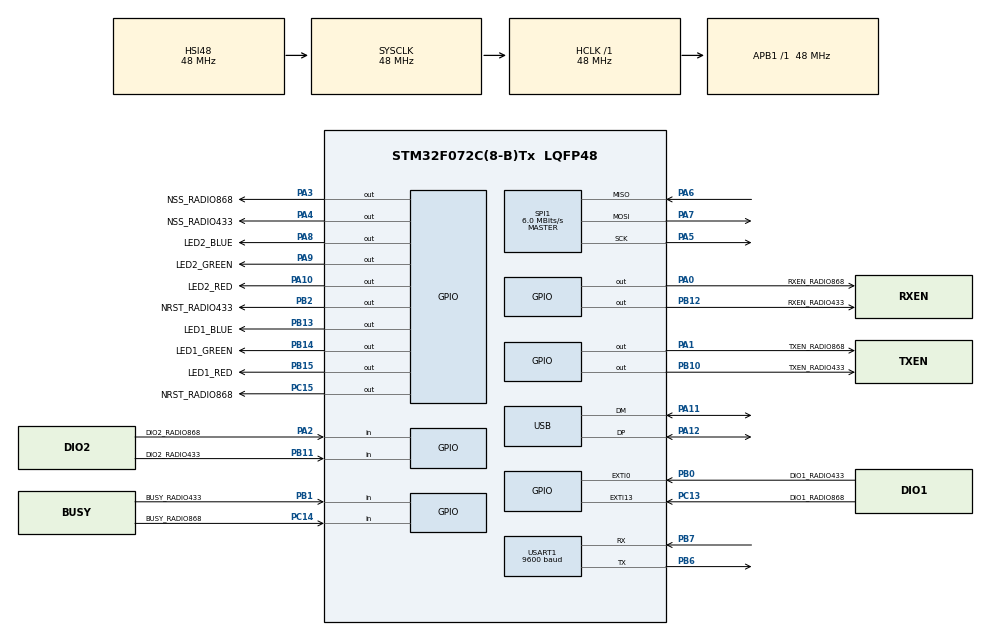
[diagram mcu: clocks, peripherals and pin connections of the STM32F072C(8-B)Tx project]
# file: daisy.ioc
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Mcu.Family=STM32F0
Mcu.Name=STM32F072C(8-B)Tx
Mcu.Package=LQFP48
NVIC.EXTI0_1_IRQn=true\:0\:0\:false\:false\:true\:true\:true
NVIC.EXTI4_15_IRQn=true\:0\:0\:false\:false\:true\:true\:true
NVIC.USART1_IRQn=true\:0\:0\:false\:false\:true\:true\:true
NVIC.USB_IRQn=true\:0\:0\:false\:false\:true\:false\:true
PA0.GPIO_Label=RXEN_RADIO868
PA0.Signal=GPIO_Output
PA1.GPIO_Label=TXEN_RADIO868
PA1.Signal=GPIO_Output
PA10.GPIO_Label=LED2_RED
PA10.Signal=GPIO_Output
PA11.Mode=Device
PA11.Signal=USB_DM
PA12.Mode=Device
PA12.Signal=USB_DP
PA13.Mode=Serial_Wire
PA13.Signal=SYS_SWDIO
PA14.Mode=Serial_Wire
PA14.Signal=SYS_SWCLK
PA2.GPIO_Label=DIO2_RADIO868
PA2.GPIO_PuPd=GPIO_PULLUP
PA2.Signal=GPIO_Input
PA3.GPIO_Label=NSS_RADIO868
PA3.PinState=GPIO_PIN_SET
PA3.Signal=GPIO_Output
PA4.GPIO_Label=NSS_RADIO433
PA4.PinState=GPIO_PIN_SET
PA4.Signal=GPIO_Output
PA5.Mode=Full_Duplex_Master
PA5.Signal=SPI1_SCK
PA6.GPIO_PuPd=GPIO_PULLUP
PA6.Mode=Full_Duplex_Master
PA6.Signal=SPI1_MISO
PA7.Mode=Full_Duplex_Master
PA7.Signal=SPI1_MOSI
PA8.GPIO_Label=LED2_BLUE
PA8.Signal=GPIO_Output
PA9.GPIO_Label=LED2_GREEN
PA9.Signal=GPIO_Output
PB0.GPIO_Label=DIO1_RADIO433
PB0.GPIO_ModeDefaultEXTI=GPIO_MODE_IT_RISING
PB0.GPIO_PuPd=GPIO_PULLDOWN
PB0.Signal=GPXTI0
PB1.GPIO_Label=BUSY_RADIO433
PB1.Signal=GPIO_Input
PB10.GPIO_Label=TXEN_RADIO433
PB10.Signal=GPIO_Output
PB11.GPIO_Label=DIO2_RADIO433
PB11.GPIO_PuPd=GPIO_PULLUP
PB11.Signal=GPIO_Input
PB12.GPIO_Label=RXEN_RADIO433
PB12.Signal=GPIO_Output
PB13.GPIO_Label=LED1_BLUE
PB13.Signal=GPIO_Output
PB14.GPIO_Label=LED1_GREEN
PB14.Signal=GPIO_Output
PB15.GPIO_Label=LED1_RED
PB15.Signal=GPIO_Output
PB2.GPIO_Label=NRST_RADIO433
PB2.Signal=GPIO_Output
PB6.Mode=Asynchronous
PB6.Signal=USART1_TX
PB7.GPIO_PuPd=GPIO_PULLUP
PB7.Mode=Asynchronous
PB7.Signal=USART1_RX
PC13.GPIO_Label=DIO1_RADIO868
PC13.GPIO_ModeDefaultEXTI=GPIO_MODE_IT_RISING
PC13.GPIO_PuPd=GPIO_PULLDOWN
PC13.Signal=GPXTI13
PC14-OSC32_IN.GPIO_Label=BUSY_RADIO868
PC14-OSC32_IN.Signal=GPIO_Input
PC15-OSC32_OUT.GPIO_Label=NRST_RADIO868
PC15-OSC32_OUT.Signal=GPIO_Output
ProjectManager.HeapSize=0x200
ProjectManager.StackSize=0x400
ProjectManager.TargetToolchain=STM32CubeIDE
RCC.AHBFreq_Value=48000000
RCC.APB1Freq_Value=48000000
RCC.APB1TimFreq_Value=48000000
RCC.HCLKFreq_Value=48000000
RCC.SYSCLKFreq_VALUE=48000000
RCC.SYSCLKSource=RCC_SYSCLKSOURCE_HSI48
SPI1.BaudRatePrescaler=SPI_BAUDRATEPRESCALER_8
SPI1.CalculateBaudRate=6.0 MBits/s
SPI1.DataSize=SPI_DATASIZE_8BIT
SPI1.Direction=SPI_DIRECTION_2LINES
SPI1.Mode=SPI_MODE_MASTER
SPI1.VirtualType=VM_MASTER
USART1.BaudRate=9600
USART1.OverrunDisableParam=ADVFEATURE_OVERRUN_DISABLE
USART1.VirtualMode-Asynchronous=VM_ASYNC
USB_DEVICE.CLASS_NAME_FS=CDC
USB_DEVICE.VirtualMode=Cdc
USB_DEVICE.VirtualModeFS=Cdc_FS
VP_RCC_USB.Mode=CRS SYNC Source USB
VP_USB_DEVICE_VS_USB_DEVICE_CDC_FS.Mode=CDC_FS
board=custom

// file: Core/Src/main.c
/* USER CODE BEGIN Header */
/**
  ******************************************************************************
  * @file           : main.c
  * @brief          : Main program body
  ******************************************************************************
  * @attention
  *
  * <h2><center>&copy; Copyright (c) 2020 STMicroelectronics.
  * All rights reserved.</center></h2>
  *
  * This software component is licensed by ST under Ultimate Liberty license
  * SLA0044, the "License"; You may not use this file except in compliance with
  * the License. You may obtain a copy of the License at:
  *                             www.st.com/SLA0044
  *
  ******************************************************************************
  */
/* USER CODE END Header */
#include "main.h"
#include "usb_device.h"

SPI_HandleTypeDef hspi1;

UART_HandleTypeDef huart1;

void SystemClock_Config(void);
static void MX_GPIO_Init(void);
static void MX_SPI1_Init(void);
static void MX_USART1_UART_Init(void);

int main(void)
{

  /* MCU Configuration--------------------------------------------------------*/

  /* Reset of all peripherals, Initializes the Flash interface and the Systick. */
  HAL_Init();

  /* Configure the system clock */
  SystemClock_Config();

  /* Initialize all configured peripherals */
  MX_GPIO_Init();
  MX_SPI1_Init();
  MX_USB_DEVICE_Init();
  MX_USART1_UART_Init();
  /* USER CODE BEGIN 2 */
  extern void SetupDaisy(void);
  SetupDaisy();

  /* USER CODE END 2 */

  /* Infinite loop */
  while (1)
  {

    /* USER CODE BEGIN 3 */
    extern void LoopDaisy(void);
    LoopDaisy();
  }
  /* USER CODE END 3 */
}

void SystemClock_Config(void)
{
  RCC_OscInitTypeDef RCC_OscInitStruct = {0};
  RCC_ClkInitTypeDef RCC_ClkInitStruct = {0};
  RCC_PeriphCLKInitTypeDef PeriphClkInit = {0};
  RCC_CRSInitTypeDef RCC_CRSInitStruct = {0};

  /** Initializes the RCC Oscillators according to the specified parameters
  * in the RCC_OscInitTypeDef structure.
  */
  RCC_OscInitStruct.OscillatorType = RCC_OSCILLATORTYPE_HSI48;
  RCC_OscInitStruct.HSI48State = RCC_HSI48_ON;
  RCC_OscInitStruct.PLL.PLLState = RCC_PLL_NONE;
  if (HAL_RCC_OscConfig(&RCC_OscInitStruct) != HAL_OK)
  {
    Error_Handler();
  }
  /** Initializes the CPU, AHB and APB buses clocks
  */
  RCC_ClkInitStruct.ClockType = RCC_CLOCKTYPE_HCLK|RCC_CLOCKTYPE_SYSCLK
                              |RCC_CLOCKTYPE_PCLK1;
  RCC_ClkInitStruct.SYSCLKSource = RCC_SYSCLKSOURCE_HSI48;
  RCC_ClkInitStruct.AHBCLKDivider = RCC_SYSCLK_DIV1;
  RCC_ClkInitStruct.APB1CLKDivider = RCC_HCLK_DIV1;

  if (HAL_RCC_ClockConfig(&RCC_ClkInitStruct, FLASH_LATENCY_1) != HAL_OK)
  {
    Error_Handler();
  }
  PeriphClkInit.PeriphClockSelection = RCC_PERIPHCLK_USB|RCC_PERIPHCLK_USART1;
  PeriphClkInit.Usart1ClockSelection = RCC_USART1CLKSOURCE_PCLK1;
  PeriphClkInit.UsbClockSelection = RCC_USBCLKSOURCE_HSI48;

  if (HAL_RCCEx_PeriphCLKConfig(&PeriphClkInit) != HAL_OK)
  {
    Error_Handler();
  }
  /** Enable the SYSCFG APB clock
  */
  __HAL_RCC_CRS_CLK_ENABLE();
  /** Configures CRS
  */
  RCC_CRSInitStruct.Prescaler = RCC_CRS_SYNC_DIV1;
  RCC_CRSInitStruct.Source = RCC_CRS_SYNC_SOURCE_USB;
  RCC_CRSInitStruct.Polarity = RCC_CRS_SYNC_POLARITY_RISING;
  RCC_CRSInitStruct.ReloadValue = __HAL_RCC_CRS_RELOADVALUE_CALCULATE(48000000,1000);
  RCC_CRSInitStruct.ErrorLimitValue = 34;
  RCC_CRSInitStruct.HSI48CalibrationValue = 32;

  HAL_RCCEx_CRSConfig(&RCC_CRSInitStruct);
}

static void MX_SPI1_Init(void)
{

  /* SPI1 parameter configuration*/
  hspi1.Instance = SPI1;
  hspi1.Init.Mode = SPI_MODE_MASTER;
  hspi1.Init.Direction = SPI_DIRECTION_2LINES;
  hspi1.Init.DataSize = SPI_DATASIZE_8BIT;
  hspi1.Init.CLKPolarity = SPI_POLARITY_LOW;
  hspi1.Init.CLKPhase = SPI_PHASE_1EDGE;
  hspi1.Init.NSS = SPI_NSS_SOFT;
  hspi1.Init.BaudRatePrescaler = SPI_BAUDRATEPRESCALER_8;
  hspi1.Init.FirstBit = SPI_FIRSTBIT_MSB;
  hspi1.Init.TIMode = SPI_TIMODE_DISABLE;
  hspi1.Init.CRCCalculation = SPI_CRCCALCULATION_DISABLE;
  hspi1.Init.CRCPolynomial = 7;
  hspi1.Init.CRCLength = SPI_CRC_LENGTH_DATASIZE;
  hspi1.Init.NSSPMode = SPI_NSS_PULSE_ENABLE;
  if (HAL_SPI_Init(&hspi1) != HAL_OK)
  {
    Error_Handler();
  }

}

static void MX_USART1_UART_Init(void)
{

  huart1.Instance = USART1;
  huart1.Init.BaudRate = 9600;
  huart1.Init.WordLength = UART_WORDLENGTH_8B;
  huart1.Init.StopBits = UART_STOPBITS_1;
  huart1.Init.Parity = UART_PARITY_NONE;
  huart1.Init.Mode = UART_MODE_TX_RX;
  huart1.Init.HwFlowCtl = UART_HWCONTROL_NONE;
  huart1.Init.OverSampling = UART_OVERSAMPLING_16;
  huart1.Init.OneBitSampling = UART_ONE_BIT_SAMPLE_DISABLE;
  huart1.AdvancedInit.AdvFeatureInit = UART_ADVFEATURE_RXOVERRUNDISABLE_INIT;
  huart1.AdvancedInit.OverrunDisable = UART_ADVFEATURE_OVERRUN_DISABLE;
  if (HAL_UART_Init(&huart1) != HAL_OK)
  {
    Error_Handler();
  }

}

static void MX_GPIO_Init(void)
{
  GPIO_InitTypeDef GPIO_InitStruct = {0};

  /* GPIO Ports Clock Enable */
  __HAL_RCC_GPIOC_CLK_ENABLE();
  __HAL_RCC_GPIOF_CLK_ENABLE();
  __HAL_RCC_GPIOA_CLK_ENABLE();
  __HAL_RCC_GPIOB_CLK_ENABLE();

  /*Configure GPIO pin Output Level */
  HAL_GPIO_WritePin(NRST_RADIO868_GPIO_Port, NRST_RADIO868_Pin, GPIO_PIN_RESET);

  /*Configure GPIO pin Output Level */
  HAL_GPIO_WritePin(GPIOA, RXEN_RADIO868_Pin|TXEN_RADIO868_Pin|LED2_BLUE_Pin|LED2_GREEN_Pin
                          |LED2_RED_Pin, GPIO_PIN_RESET);

  /*Configure GPIO pin Output Level */
  HAL_GPIO_WritePin(GPIOA, NSS_RADIO868_Pin|NSS_RADIO433_Pin, GPIO_PIN_SET);

  /*Configure GPIO pin Output Level */
  HAL_GPIO_WritePin(GPIOB, NRST_RADIO433_Pin|TXEN_RADIO433_Pin|RXEN_RADIO433_Pin|LED1_BLUE_Pin
                          |LED1_GREEN_Pin|LED1_RED_Pin, GPIO_PIN_RESET);

  /*Configure GPIO pin : DIO1_RADIO868_Pin */
  GPIO_InitStruct.Pin = DIO1_RADIO868_Pin;
  GPIO_InitStruct.Mode = GPIO_MODE_IT_RISING;
  GPIO_InitStruct.Pull = GPIO_PULLDOWN;
  HAL_GPIO_Init(DIO1_RADIO868_GPIO_Port, &GPIO_InitStruct);

  /*Configure GPIO pin : BUSY_RADIO868_Pin */
  GPIO_InitStruct.Pin = BUSY_RADIO868_Pin;
  GPIO_InitStruct.Mode = GPIO_MODE_INPUT;
  GPIO_InitStruct.Pull = GPIO_NOPULL;
  HAL_GPIO_Init(BUSY_RADIO868_GPIO_Port, &GPIO_InitStruct);

  /*Configure GPIO pin : NRST_RADIO868_Pin */
  GPIO_InitStruct.Pin = NRST_RADIO868_Pin;
  GPIO_InitStruct.Mode = GPIO_MODE_OUTPUT_PP;
  GPIO_InitStruct.Pull = GPIO_NOPULL;
  GPIO_InitStruct.Speed = GPIO_SPEED_FREQ_LOW;
  HAL_GPIO_Init(NRST_RADIO868_GPIO_Port, &GPIO_InitStruct);

  /*Configure GPIO pins : PF0 PF1 */
  GPIO_InitStruct.Pin = GPIO_PIN_0|GPIO_PIN_1;
  GPIO_InitStruct.Mode = GPIO_MODE_ANALOG;
  GPIO_InitStruct.Pull = GPIO_NOPULL;
  HAL_GPIO_Init(GPIOF, &GPIO_InitStruct);

  /*Configure GPIO pins : RXEN_RADIO868_Pin TXEN_RADIO868_Pin NSS_RADIO868_Pin NSS_RADIO433_Pin
                           LED2_BLUE_Pin LED2_GREEN_Pin LED2_RED_Pin */
  GPIO_InitStruct.Pin = RXEN_RADIO868_Pin|TXEN_RADIO868_Pin|NSS_RADIO868_Pin|NSS_RADIO433_Pin
                          |LED2_BLUE_Pin|LED2_GREEN_Pin|LED2_RED_Pin;
  GPIO_InitStruct.Mode = GPIO_MODE_OUTPUT_PP;
  GPIO_InitStruct.Pull = GPIO_NOPULL;
  GPIO_InitStruct.Speed = GPIO_SPEED_FREQ_LOW;
  HAL_GPIO_Init(GPIOA, &GPIO_InitStruct);

  /*Configure GPIO pin : DIO2_RADIO868_Pin */
  GPIO_InitStruct.Pin = DIO2_RADIO868_Pin;
  GPIO_InitStruct.Mode = GPIO_MODE_INPUT;
  GPIO_InitStruct.Pull = GPIO_PULLUP;
  HAL_GPIO_Init(DIO2_RADIO868_GPIO_Port, &GPIO_InitStruct);

  /*Configure GPIO pin : DIO1_RADIO433_Pin */
  GPIO_InitStruct.Pin = DIO1_RADIO433_Pin;
  GPIO_InitStruct.Mode = GPIO_MODE_IT_RISING;
  GPIO_InitStruct.Pull = GPIO_PULLDOWN;
  HAL_GPIO_Init(DIO1_RADIO433_GPIO_Port, &GPIO_InitStruct);

  /*Configure GPIO pin : BUSY_RADIO433_Pin */
  GPIO_InitStruct.Pin = BUSY_RADIO433_Pin;
  GPIO_InitStruct.Mode = GPIO_MODE_INPUT;
  GPIO_InitStruct.Pull = GPIO_NOPULL;
  HAL_GPIO_Init(BUSY_RADIO433_GPIO_Port, &GPIO_InitStruct);

  /*Configure GPIO pins : NRST_RADIO433_Pin TXEN_RADIO433_Pin RXEN_RADIO433_Pin LED1_BLUE_Pin
                           LED1_GREEN_Pin LED1_RED_Pin */
  GPIO_InitStruct.Pin = NRST_RADIO433_Pin|TXEN_RADIO433_Pin|RXEN_RADIO433_Pin|LED1_BLUE_Pin
                          |LED1_GREEN_Pin|LED1_RED_Pin;
  GPIO_InitStruct.Mode = GPIO_MODE_OUTPUT_PP;
  GPIO_InitStruct.Pull = GPIO_NOPULL;
  GPIO_InitStruct.Speed = GPIO_SPEED_FREQ_LOW;
  HAL_GPIO_Init(GPIOB, &GPIO_InitStruct);

  /*Configure GPIO pin : DIO2_RADIO433_Pin */
  GPIO_InitStruct.Pin = DIO2_RADIO433_Pin;
  GPIO_InitStruct.Mode = GPIO_MODE_INPUT;
  GPIO_InitStruct.Pull = GPIO_PULLUP;
  HAL_GPIO_Init(DIO2_RADIO433_GPIO_Port, &GPIO_InitStruct);

  /*Configure GPIO pin : PA15 */
  GPIO_InitStruct.Pin = GPIO_PIN_15;
  GPIO_InitStruct.Mode = GPIO_MODE_ANALOG;
  GPIO_InitStruct.Pull = GPIO_NOPULL;
  HAL_GPIO_Init(GPIOA, &GPIO_InitStruct);

  /*Configure GPIO pins : PB3 PB4 PB5 PB8
                           PB9 */
  GPIO_InitStruct.Pin = GPIO_PIN_3|GPIO_PIN_4|GPIO_PIN_5|GPIO_PIN_8
                          |GPIO_PIN_9;
  GPIO_InitStruct.Mode = GPIO_MODE_ANALOG;
  GPIO_InitStruct.Pull = GPIO_NOPULL;
  HAL_GPIO_Init(GPIOB, &GPIO_InitStruct);

  /* EXTI interrupt init*/
  HAL_NVIC_SetPriority(EXTI0_1_IRQn, 0, 0);
  HAL_NVIC_EnableIRQ(EXTI0_1_IRQn);

  HAL_NVIC_SetPriority(EXTI4_15_IRQn, 0, 0);
  HAL_NVIC_EnableIRQ(EXTI4_15_IRQn);

}

void Error_Handler(void)
{
}

/************************ (C) COPYRIGHT STMicroelectronics *****END OF FILE****/
